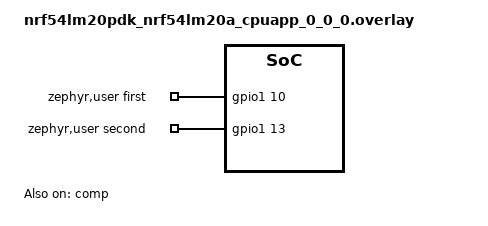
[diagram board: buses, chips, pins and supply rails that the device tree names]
/ {
	aliases {
		test-comp = &comp;
	};

	zephyr,user {
		first-gpios = <&gpio1 10 GPIO_ACTIVE_HIGH>;
		second-gpios = <&gpio1 13 GPIO_ACTIVE_HIGH>;
	};
};

&gpio1 {
	status = "okay";
};

&comp {
	status = "okay";
	psel = "AIN4";
	refsel = "AREF";
	extrefsel= "AIN3";
	sp-mode = "NORMAL";
	th-up = <36>;
	th-down = <30>;
	isource = "DISABLED";
	enable-hyst;
};
